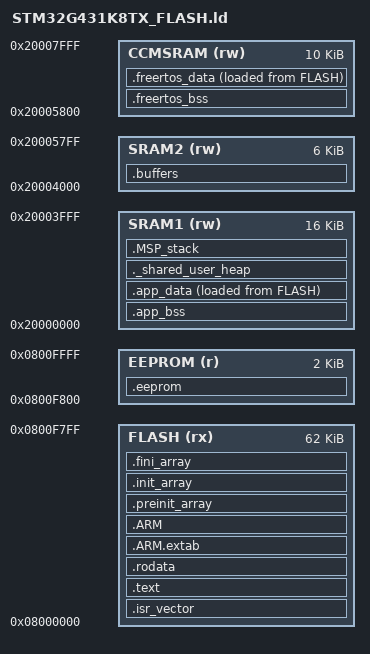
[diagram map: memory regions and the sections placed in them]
/*
******************************************************************************
**
** @file        : LinkerScript.ld
**
** @author      : Auto-generated by STM32CubeIDE
**
** @brief       : Linker script for STM32G431K8Tx Device from STM32G4 series
**                      64KBytes FLASH
**                      32KBytes RAM
**
**                Set heap size, stack size and stack location according
**                to application requirements.
**
**                Set memory bank area and size if external memory is used
**
**  Target      : STMicroelectronics STM32
**
**  Distribution: The file is distributed as is, without any warranty
**                of any kind.
**
******************************************************************************
** @attention
**
** Copyright (c) 2024 STMicroelectronics.
** All rights reserved.
**
** This software is licensed under terms that can be found in the LICENSE file
** in the root directory of this software component.
** If no LICENSE file comes with this software, it is provided AS-IS.
**
******************************************************************************
*/

/* Entry Point */
ENTRY(Reset_Handler)

_Min_Heap_Size = 0x200; /* required amount of heap */
_Min_Stack_Size = 0x400; /* required amount of stack */

/* Memories definition */
MEMORY
{
  SRAM1 (rw) : ORIGIN = 0x20000000, LENGTH = 16K
  SRAM2 (rw) : ORIGIN = 0x20004000, LENGTH = 6K
  CCMSRAM (rw) : ORIGIN = 0x20005800, LENGTH = 10K
  FLASH (rx) : ORIGIN = 0x8000000, LENGTH = 64K - 2K
  EEPROM (r) : ORIGIN = ORIGIN(FLASH) + LENGTH(FLASH), LENGTH = 2K
}

null_ptr = 0;

/* Sections */
SECTIONS
{
  /* The startup code into "FLASH" Rom type memory */
  .isr_vector :
  {
    . = ALIGN(4);
    KEEP(*(.isr_vector)) /* Startup code */
    . = ALIGN(4);
  } >FLASH

  /* The program code and other data into "FLASH" Rom type memory */
  .text :
  {
    . = ALIGN(4);
    *(.text)           /* .text sections (code) */
    *(.text*)          /* .text* sections (code) */
    *(.glue_7)         /* glue arm to thumb code */
    *(.glue_7t)        /* glue thumb to arm code */
    *(.eh_frame)

    KEEP (*(.init))
    KEEP (*(.fini))

    . = ALIGN(4);
    _etext = .;        /* define a global symbols at end of code */
  } >FLASH

  /* Constant data into "FLASH" Rom type memory */
  .rodata :
  {
    . = ALIGN(4);
    *(.rodata)         /* .rodata sections (constants, strings, etc.) */
    *(.rodata*)        /* .rodata* sections (constants, strings, etc.) */
    . = ALIGN(4);
  } >FLASH

  .ARM.extab (READONLY) : /* The "READONLY" keyword is only supported in GCC11 and later, remove it if using GCC10 or earlier. */
  {
    . = ALIGN(4);
    *(.ARM.extab* .gnu.linkonce.armextab.*)
    . = ALIGN(4);
  } >FLASH

  .ARM (READONLY) : /* The "READONLY" keyword is only supported in GCC11 and later, remove it if using GCC10 or earlier. */
  {
    . = ALIGN(4);
    __exidx_start = .;
    *(.ARM.exidx*)
    __exidx_end = .;
    . = ALIGN(4);
  } >FLASH

  .preinit_array (READONLY) : /* The "READONLY" keyword is only supported in GCC11 and later, remove it if using GCC10 or earlier. */
  {
    . = ALIGN(4);
    PROVIDE_HIDDEN (__preinit_array_start = .);
    KEEP (*(.preinit_array*))
    PROVIDE_HIDDEN (__preinit_array_end = .);
    . = ALIGN(4);
  } >FLASH

  .init_array (READONLY) : /* The "READONLY" keyword is only supported in GCC11 and later, remove it if using GCC10 or earlier. */
  {
    . = ALIGN(4);
    PROVIDE_HIDDEN (__init_array_start = .);
    KEEP (*(SORT(.init_array.*)))
    KEEP (*(.init_array*))
    PROVIDE_HIDDEN (__init_array_end = .);
    . = ALIGN(4);
  } >FLASH

  .fini_array (READONLY) : /* The "READONLY" keyword is only supported in GCC11 and later, remove it if using GCC10 or earlier. */
  {
    . = ALIGN(4);
    PROVIDE_HIDDEN (__fini_array_start = .);
    KEEP (*(SORT(.fini_array.*)))
    KEEP (*(.fini_array*))
    PROVIDE_HIDDEN (__fini_array_end = .);
    . = ALIGN(4);
  } >FLASH
	
	.freertos_bss (NOLOAD) :
	{
		. = ALIGN(4);
		_freertos_bss_run_addr = .;
		
		*(.stack)
		./lib/FreeRTOS-Kernel/*.o(.bss*) /* */ ./glue/FreeRTOS-Kernel/*.o(.bss*) /* */
		
		. = ALIGN(4);
		_freertos_bss_end = .;
	} >CCMSRAM

	.freertos_data :
	{
		. = ALIGN(4);
		_freertos_data_run_addr = .;
		
		./lib/FreeRTOS-Kernel/*.o(.data*) /* */ ./glue/FreeRTOS-Kernel/*.o(.data*) /* */
		
		. = ALIGN(4);
		_freertos_data_end = .;
	} >CCMSRAM AT> FLASH
	_freertos_data_load_addr = LOADADDR(.freertos_data);
	
	.app_bss (NOLOAD) :
	{
		. = ALIGN(4);
		_app_bss_run_addr = .;
		
	    *(.bss)
	    *(.bss*)
	    *(COMMON)
		
		. = ALIGN(4);
		_app_bss_end = .;
	} >SRAM1

	.app_data :
	{
		. = ALIGN(4);
		_app_data_run_addr = .;
		
	    *(.data)           /* .data sections */
	    *(.data*)          /* .data* sections */
	    *(.RamFunc)        /* .RamFunc sections */
	    *(.RamFunc*)       /* .RamFunc* sections */
		
		. = ALIGN(4);
		_app_data_end = .;
	} >SRAM1 AT> FLASH
	_app_data_load_addr = LOADADDR(.app_data);
	
	._shared_user_heap :
	{
		_shared_bss_run_addr = .;
		__SHARED_SRAM_segment_start__ = .;
		. = 1;
		. = ALIGN(4);
		PROVIDE ( end = . );
		PROVIDE ( _end = . );
		. = . + _Min_Heap_Size;
		. = ALIGN(4);
		_eheap = .;
	} >SRAM1
	
	.MSP_stack :
	{
		. = ALIGN(8);
		. = . + _Min_Stack_Size;
		. = ALIGN(8);
		_estack = .;
	} >SRAM1
	
	.buffers :
	{
		*(.buffers)
	} >SRAM2
	
	.eeprom (NOLOAD) :
	{
		_eeprom = .;
		. = LENGTH(EEPROM);
		_eeprom_end = .;
	} > EEPROM = 0xFF

  /* Remove information from the compiler libraries */
  /DISCARD/ :
  {
    libc.a ( * )
    libm.a ( * )
    libgcc.a ( * )
  }

  .ARM.attributes 0 : { *(.ARM.attributes) }
}
